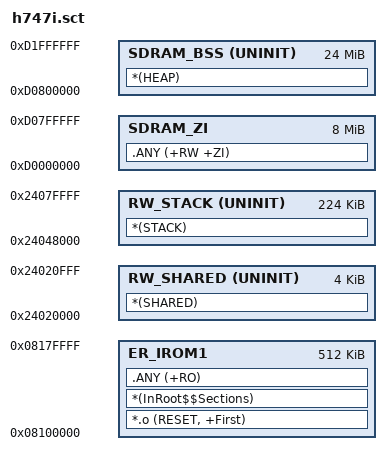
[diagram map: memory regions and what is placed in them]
LR_IROM1 0x08100000 0x00080000 {    ; load region size_region
  ER_IROM1 0x08100000 0x00080000 {  ; load address = execution address
   *.o (RESET, +First)
   *(InRoot$$Sections)
   .ANY (+RO)
  }
  RW_SHARED 0x24020000 UNINIT 0x00001000  { ;SRAM1
   *(SHARED)
  }
  RW_STACK 0x24048000 UNINIT 0x00038000  { ;SRAM2
   *(STACK)
  }
  SDRAM_ZI 0xD0000000 0x00800000 {  ; SDRAM
    .ANY (+RW +ZI)
  }
  SDRAM_BSS 0xD0800000 UNINIT 0x01800000  {  ; SDRAM
    *(HEAP)
  }
}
